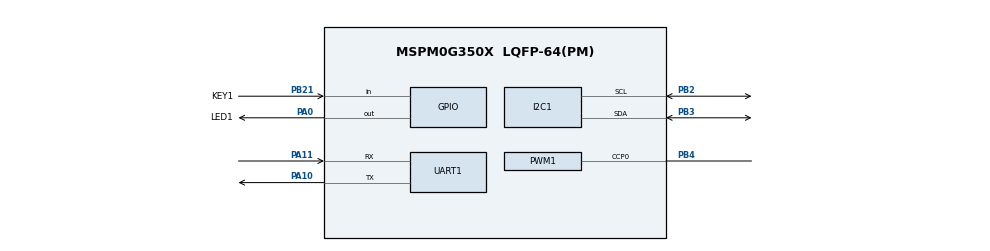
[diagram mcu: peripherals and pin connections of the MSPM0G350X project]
/**
 * @cliArgs --device "MSPM0G350X" --part "Default" --package "LQFP-64(PM)" --product "mspm0_sdk@2.05.00.05"
 * @versions {"tool":"1.24.0+4110"}
 */

/**
 * Import the modules used in this configuration.
 */
const GPIO    = scripting.addModule("/ti/driverlib/GPIO", {}, false);
const GPIO1   = GPIO.addInstance();
const GPIO2   = GPIO.addInstance();
const I2C     = scripting.addModule("/ti/driverlib/I2C", {}, false);
const I2C1    = I2C.addInstance();
const PWM     = scripting.addModule("/ti/driverlib/PWM", {}, false);
const PWM1    = PWM.addInstance();
const SYSCTL  = scripting.addModule("/ti/driverlib/SYSCTL");
const SYSTICK = scripting.addModule("/ti/driverlib/SYSTICK");
const UART    = scripting.addModule("/ti/driverlib/UART", {}, false);
const UART1   = UART.addInstance();

/**
 * Write custom configuration values to the imported modules.
 */
const gate7  = system.clockTree["MFCLKGATE"];
gate7.enable = true;

GPIO1.$name                          = "LED";
GPIO1.associatedPins[0].$name        = "LED1";
GPIO1.associatedPins[0].assignedPort = "PORTA";
GPIO1.associatedPins[0].pin.$assign  = "PA0";

const Board = scripting.addModule("/ti/driverlib/Board", {}, false);

GPIO2.$name                              = "KEY";
GPIO2.associatedPins[0].$name            = "KEY1";
GPIO2.associatedPins[0].direction        = "INPUT";
GPIO2.associatedPins[0].interruptEn      = true;
GPIO2.associatedPins[0].assignedPort     = "PORTB";
GPIO2.associatedPins[0].internalResistor = "PULL_UP";
GPIO2.associatedPins[0].polarity         = "FALL";
GPIO2.associatedPins[0].pin.$assign      = "PB21";

I2C1.$name                     = "I2C_0";
I2C1.basicEnableController     = true;
I2C1.peripheral.sdaPin.$assign = "PB3";
I2C1.peripheral.sclPin.$assign = "PB2";
I2C1.sdaPinConfig.$name        = "ti_driverlib_gpio_GPIOPinGeneric3";
I2C1.sclPinConfig.$name        = "ti_driverlib_gpio_GPIOPinGeneric4";

PWM1.$name                      = "PWM_0";
PWM1.timerStartTimer            = true;
PWM1.ccIndex                    = [0];
PWM1.timerCount                 = 50000;
PWM1.clockSource                = "LFCLK";
PWM1.PWM_CHANNEL_0.$name        = "ti_driverlib_pwm_PWMTimerCC0";
PWM1.PWM_CHANNEL_0.dutyCycle    = 50;
PWM1.ccp0PinConfig.$name        = "ti_driverlib_gpio_GPIOPinGeneric2";
PWM1.peripheral.$assign         = "TIMA1";
PWM1.peripheral.ccp0Pin.$assign = "PB4";

SYSCTL.forceDefaultClkConfig = true;
SYSCTL.clockTreeEn           = true;

SYSTICK.periodEnable    = true;
SYSTICK.period          = 32000;
SYSTICK.interruptEnable = true;
SYSTICK.systickEnable   = true;

UART1.$name                    = "UART_0";
UART1.uartClkSrc               = "MFCLK";
UART1.enabledInterrupts        = ["RX"];
UART1.interruptPriority        = "0";
UART1.peripheral.$assign       = "UART0";
UART1.peripheral.rxPin.$assign = "PA11";
UART1.peripheral.txPin.$assign = "PA10";
UART1.txPinConfig.$name        = "ti_driverlib_gpio_GPIOPinGeneric0";
UART1.rxPinConfig.$name        = "ti_driverlib_gpio_GPIOPinGeneric1";

/**
 * Pinmux solution for unlocked pins/peripherals. This ensures that minor changes to the automatic solver in a future
 * version of the tool will not impact the pinmux you originally saw.  These lines can be completely deleted in order to
 * re-solve from scratch.
 */
Board.peripheral.$suggestSolution          = "DEBUGSS";
Board.peripheral.swclkPin.$suggestSolution = "PA20";
Board.peripheral.swdioPin.$suggestSolution = "PA19";
I2C1.peripheral.$suggestSolution           = "I2C1";
